# PIC16F1769 register map
Vendor: Microchip
Architecture 16Exxx. Special function registers and configuration words.
Registers are 8-bit, read-write, reset 0x0 unless marked. A register's access mark holds for its fields unless they carry their own. Addresses are absolute, and some are shared; only a register's first bit layout is shown; lines under a group give offsets from that group; [hi:lo] are bit positions; {n}, {i} and the like mark numbered series; 'fields as' and 'values as' point back to an identical list; <NAME> marks a mode.

## Further device data
pins=1: Vdd; 2: RA5/SOSCI/OSC1/CLKIN; 3: RA4/AN3/SOSCO/OSC2/CLKOUT; 4: RA3/Vpp/nMCLR/nICD/MCLR; 5: RC5; 6: RC4; 7: RC3/AN7/OPA2OUT/OPA1IN1-/OPA1IN1+/C1IN3-/C2IN3-/C3IN3-/C4IN3-/PRG1IN1/PRG2IN0; 8: RC6/AN8/OPA2IN0-; 9: RC7/AN9/OPA2IN0+; 10: RB7/C2IN1+/C4IN1+; 11: RB6/C1IN1+/C3IN1+; 12: RB5/AN11/OPA1IN0+; 13: RB4/AN10/OPA1IN0-; 14: RC2/AN6/OPA1OUT/OPA2IN1-/OPA2IN1+/C1IN2-/C2IN2-/PRG1IN0/PRG2IN1; 15: RC1/AN5/C1IN1-/C2IN1-/C3IN1-/C4IN1-; 16: RC0/AN4/C2IN0+/C4IN0+; 17: RA2/AN2/ZCD; 18: RA1/AN1/Vref+/DAC1Ref+/DAC2Ref+/DAC3Ref+/DAC4Ref+/C1IN0-/C2IN0-/C3IN0-/C4IN0-/ICSPCLK; 19: RA0/AN0/Vref-/DAC1Ref-/DAC2Ref-/DAC3Ref-/DAC4Ref-/DAC1OUT1/DAC2OUT1/DAC3OUT1/DAC4OUT1/C1IN0+/C3IN0+/ICSPDAT; 20: Vss

## DOS_TIMER1_tmr
0x16 TMR1L reset not defined — (power-on value xxxxxxxx)
  [7:0] TMR
0x17 TMR1H reset not defined — (power-on value xxxxxxxx)
  [7:0] TMR
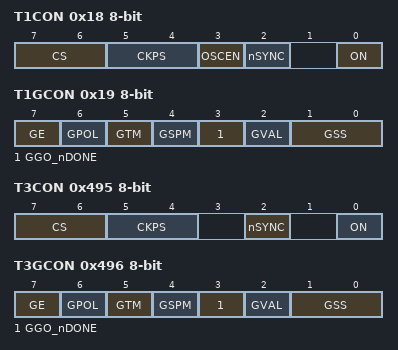
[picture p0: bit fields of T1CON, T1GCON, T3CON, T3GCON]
0x18 T1CON
  [7:6] CS, [5:4] CKPS, [3] OSCEN, [2] nSYNC, [0] ON
0x19 T1GCON reset not defined — (power-on value 00000x00)
  [7] GE, [6] GPOL, [5] GTM, [4] GSPM, [3] GGO_nDONE, [2] GVAL ro, [1:0] GSS
0x493 TMR3L reset not defined — (power-on value xxxxxxxx)
  [7:0] TMR
0x494 TMR3H reset not defined — (power-on value xxxxxxxx)
  [7:0] TMR
0x495 T3CON
  [7:6] CS, [5:4] CKPS, [2] nSYNC, [0] ON
0x496 T3GCON reset not defined — (power-on value 00000x00)
  fields as T1GCON
0x49A TMR5L reset not defined — (power-on value xxxxxxxx)
  [7:0] TMR
0x49B TMR5H reset not defined — (power-on value xxxxxxxx)
  [7:0] TMR
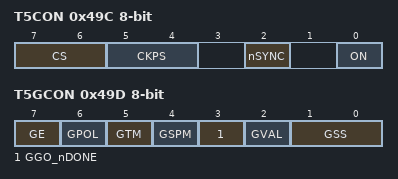
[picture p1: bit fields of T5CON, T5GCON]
0x49C T5CON
  [7:6] CS, [5:4] CKPS, [2] nSYNC, [0] ON
0x49D T5GCON reset not defined — (power-on value 00000x00)
  fields as T1GCON

## tmr
0x1A T2TMR — 8-bit period timer
  [7:0] TMR2
0x1B T2PR reset 0xFF
  [7:0] PR2
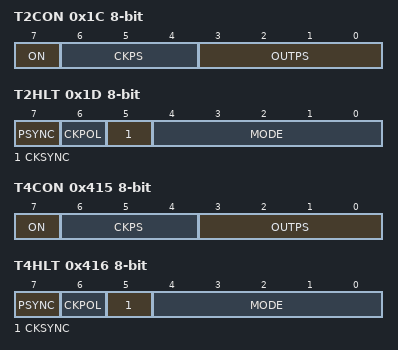
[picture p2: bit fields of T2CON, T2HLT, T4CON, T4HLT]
0x1C T2CON
  [7] ON, [6:4] CKPS, [3:0] OUTPS
0x1D T2HLT
  [7] PSYNC, [6] CKPOL, [5] CKSYNC, [4:0] MODE
0x1E T2CLKCON
  [3:0] CS
0x1F T2RST
  [4:0] RSEL
0x413 T4TMR — 8-bit period timer
  [7:0] TMR4
0x414 T4PR reset 0xFF
  [7:0] PR4
0x415 T4CON
  [7] ON, [6:4] CKPS, [3:0] OUTPS
0x416 T4HLT
  [7] PSYNC, [6] CKPOL, [5] CKSYNC, [4:0] MODE
0x417 T4CLKCON
  [3:0] CS
0x418 T4RST
  [4:0] RSEL
0x41A T6TMR — 8-bit period timer
  [7:0] TMR6
0x41B T6PR reset 0xFF
  [7:0] PR6
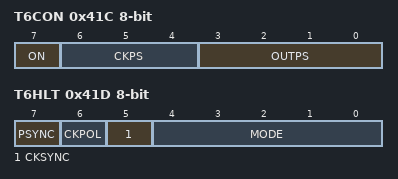
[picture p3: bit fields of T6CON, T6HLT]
0x41C T6CON
  [7] ON, [6:4] CKPS, [3:0] OUTPS
0x41D T6HLT
  [7] PSYNC, [6] CKPOL, [5] CKSYNC, [4:0] MODE
0x41E T6CLKCON
  [3:0] CS
0x41F T6RST
  [4:0] RSEL

## cmp_rr
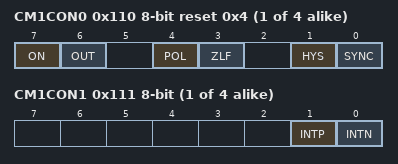
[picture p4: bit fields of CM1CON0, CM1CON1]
{0x10C+4i} CM{i}CON0 reset 0x4 (i=1..4)
  [7] ON, [6] OUT ro, [4] POL, [3] ZLF, [1] HYS, [0] SYNC
{0x10D+4i} CM{i}CON1 (i=1..4)
  [1] INTP, [0] INTN
{0x10E+4i} CM{i}NSEL (i=1..4)
  [2:0] NCH
{0x10F+4i} CM{i}PSEL (i=1..4)
  [3:0] PCH

## mssp
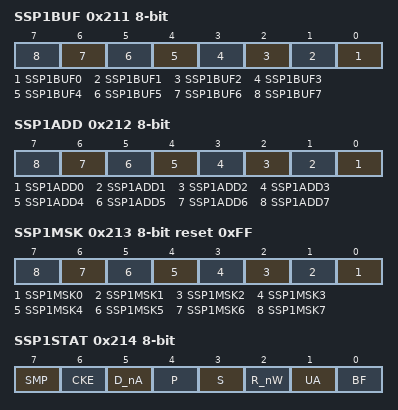
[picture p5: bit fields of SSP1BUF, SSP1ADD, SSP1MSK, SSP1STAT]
0x211 SSP1BUF reset not defined — (power-on value xxxxxxxx)
  [n] SSP1BUF{n} (n=0..7)
0x212 SSP1ADD
  [n] SSP1ADD{n} (n=0..7)
0x213 SSP1MSK reset 0xFF
  [n] SSP1MSK{n} (n=0..7)
0x214 SSP1STAT
  [7] SMP, [6] CKE, [5] D_nA ro, [4] P ro, [3] S ro, [2] R_nW ro, [1] UA ro, [0] BF ro
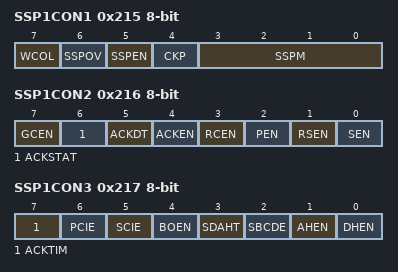
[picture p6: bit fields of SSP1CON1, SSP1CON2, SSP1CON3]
0x215 SSP1CON1
  [7] WCOL, [6] SSPOV, [5] SSPEN, [4] CKP, [3:0] SSPM
0x216 SSP1CON2
  [7] GCEN, [6] ACKSTAT ro, [5] ACKDT, [4] ACKEN, [3] RCEN, [2] PEN, [1] RSEN, [0] SEN
0x217 SSP1CON3
  [7] ACKTIM ro, [6] PCIE, [5] SCIE, [4] BOEN, [3] SDAHT, [2] SBCDE, [1] AHEN, [0] DHEN
